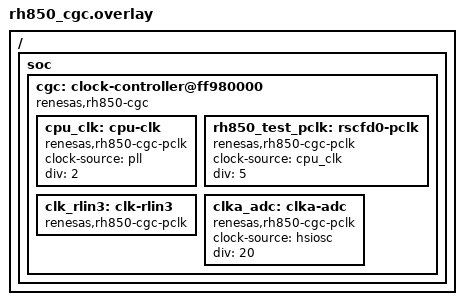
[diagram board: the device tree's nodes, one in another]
/*
 * Copyright (c) 2026 Renesas Electronics Corporation
 *
 * SPDX-License-Identifier: Apache-2.0
 */

/*
 * Test-only overlay for tests/drivers/clock_control/clock_control_api.
 * The child clock nodes intentionally exercise the pclk/sysclk/osc bindings.
 */

/ {
	soc {
		cgc: clock-controller@ff980000 {
			compatible = "renesas,rh850-cgc";
			#clock-cells = <1>;
			status = "okay";

			cpu_clk: cpu-clk {
				compatible = "renesas,rh850-cgc-pclk";
				clock-source = <&pll>;
				div = <2>;
				#clock-cells = <0>;
			};

			rh850_test_pclk: rscfd0-pclk {
				compatible = "renesas,rh850-cgc-pclk";
				clock-source = <&cpu_clk>;
				div = <5>;
				#clock-cells = <0>;
			};

			clk_rlin3: clk-rlin3 {
				compatible = "renesas,rh850-cgc-pclk";
				#clock-cells = <0>;
				status = "okay";
			};

			clka_adc: clka-adc {
				compatible = "renesas,rh850-cgc-pclk";
				clock-source = <&hsiosc>;
				div = <20>;
				#clock-cells = <0>;
				status = "okay";
			};
		};
	};
};
